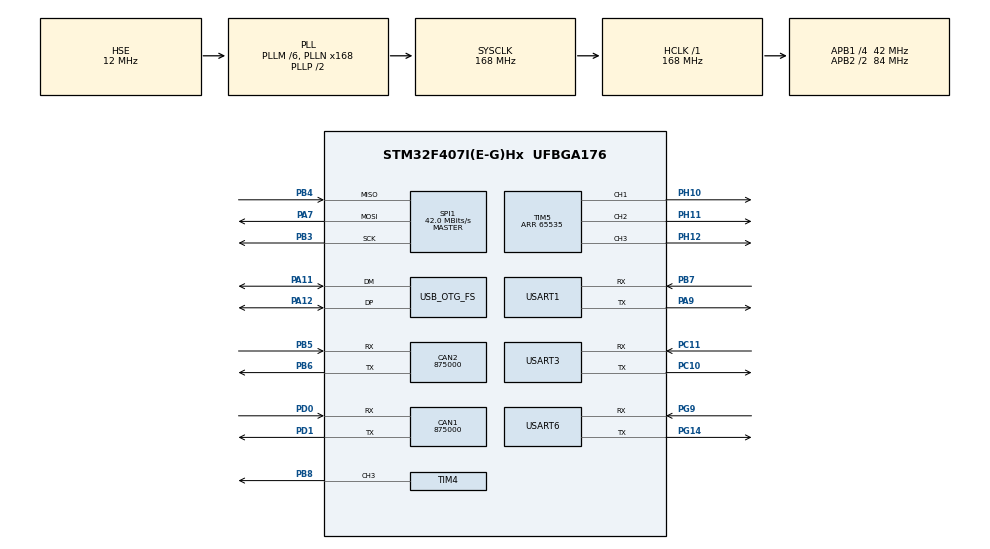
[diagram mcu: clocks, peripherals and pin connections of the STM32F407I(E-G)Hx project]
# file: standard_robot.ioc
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CAN1.CalculateBaudRate=875000
CAN1.CalculateTimeBit=1142
CAN1.CalculateTimeQuantum=380.95238095238096
CAN2.CalculateBaudRate=875000
CAN2.CalculateTimeBit=1142
CAN2.CalculateTimeQuantum=380.95238095238096
Dma.Request0=USART1_TX
Dma.Request1=USART1_RX
Dma.Request2=USART3_RX
Dma.Request3=USART6_RX
Dma.Request4=USART6_TX
Dma.Request5=SPI1_RX
Dma.Request6=SPI1_TX
Dma.SPI1_RX.5.Direction=DMA_PERIPH_TO_MEMORY
Dma.SPI1_RX.5.FIFOMode=DMA_FIFOMODE_DISABLE
Dma.SPI1_RX.5.Instance=DMA2_Stream2
Dma.SPI1_RX.5.MemDataAlignment=DMA_MDATAALIGN_BYTE
Dma.SPI1_RX.5.MemInc=DMA_MINC_ENABLE
Dma.SPI1_RX.5.Mode=DMA_NORMAL
Dma.SPI1_RX.5.PeriphDataAlignment=DMA_PDATAALIGN_BYTE
Dma.SPI1_RX.5.PeriphInc=DMA_PINC_DISABLE
Dma.SPI1_RX.5.Priority=DMA_PRIORITY_VERY_HIGH
Dma.SPI1_TX.6.Direction=DMA_MEMORY_TO_PERIPH
Dma.SPI1_TX.6.FIFOMode=DMA_FIFOMODE_DISABLE
Dma.SPI1_TX.6.Instance=DMA2_Stream3
Dma.SPI1_TX.6.MemDataAlignment=DMA_MDATAALIGN_BYTE
Dma.SPI1_TX.6.MemInc=DMA_MINC_ENABLE
Dma.SPI1_TX.6.Mode=DMA_NORMAL
Dma.SPI1_TX.6.PeriphDataAlignment=DMA_PDATAALIGN_BYTE
Dma.SPI1_TX.6.PeriphInc=DMA_PINC_DISABLE
Dma.SPI1_TX.6.Priority=DMA_PRIORITY_HIGH
Dma.USART1_RX.1.Direction=DMA_PERIPH_TO_MEMORY
Dma.USART1_RX.1.FIFOMode=DMA_FIFOMODE_DISABLE
Dma.USART1_RX.1.Instance=DMA2_Stream5
Dma.USART1_RX.1.MemDataAlignment=DMA_MDATAALIGN_BYTE
Dma.USART1_RX.1.MemInc=DMA_MINC_ENABLE
Dma.USART1_RX.1.Mode=DMA_CIRCULAR
Dma.USART1_RX.1.PeriphDataAlignment=DMA_PDATAALIGN_BYTE
Dma.USART1_RX.1.PeriphInc=DMA_PINC_DISABLE
Dma.USART1_RX.1.Priority=DMA_PRIORITY_MEDIUM
Dma.USART1_TX.0.Direction=DMA_MEMORY_TO_PERIPH
Dma.USART1_TX.0.FIFOMode=DMA_FIFOMODE_DISABLE
Dma.USART1_TX.0.Instance=DMA2_Stream7
Dma.USART1_TX.0.MemDataAlignment=DMA_MDATAALIGN_BYTE
Dma.USART1_TX.0.MemInc=DMA_MINC_ENABLE
Dma.USART1_TX.0.Mode=DMA_NORMAL
Dma.USART1_TX.0.PeriphDataAlignment=DMA_PDATAALIGN_BYTE
Dma.USART1_TX.0.PeriphInc=DMA_PINC_DISABLE
Dma.USART1_TX.0.Priority=DMA_PRIORITY_MEDIUM
Dma.USART3_RX.2.Direction=DMA_PERIPH_TO_MEMORY
Dma.USART3_RX.2.FIFOMode=DMA_FIFOMODE_DISABLE
Dma.USART3_RX.2.Instance=DMA1_Stream1
Dma.USART3_RX.2.MemDataAlignment=DMA_MDATAALIGN_BYTE
Dma.USART3_RX.2.MemInc=DMA_MINC_ENABLE
Dma.USART3_RX.2.Mode=DMA_CIRCULAR
Dma.USART3_RX.2.PeriphDataAlignment=DMA_PDATAALIGN_BYTE
Dma.USART3_RX.2.PeriphInc=DMA_PINC_DISABLE
Dma.USART3_RX.2.Priority=DMA_PRIORITY_MEDIUM
Dma.USART6_RX.3.Direction=DMA_PERIPH_TO_MEMORY
Dma.USART6_RX.3.FIFOMode=DMA_FIFOMODE_DISABLE
Dma.USART6_RX.3.Instance=DMA2_Stream1
Dma.USART6_RX.3.MemDataAlignment=DMA_MDATAALIGN_BYTE
Dma.USART6_RX.3.MemInc=DMA_MINC_ENABLE
Dma.USART6_RX.3.Mode=DMA_NORMAL
Dma.USART6_RX.3.PeriphDataAlignment=DMA_PDATAALIGN_BYTE
Dma.USART6_RX.3.PeriphInc=DMA_PINC_DISABLE
Dma.USART6_RX.3.Priority=DMA_PRIORITY_MEDIUM
Dma.USART6_TX.4.Direction=DMA_MEMORY_TO_PERIPH
Dma.USART6_TX.4.FIFOMode=DMA_FIFOMODE_DISABLE
Dma.USART6_TX.4.Instance=DMA2_Stream6
Dma.USART6_TX.4.MemDataAlignment=DMA_MDATAALIGN_BYTE
Dma.USART6_TX.4.MemInc=DMA_MINC_ENABLE
Dma.USART6_TX.4.Mode=DMA_NORMAL
Dma.USART6_TX.4.PeriphDataAlignment=DMA_PDATAALIGN_BYTE
Dma.USART6_TX.4.PeriphInc=DMA_PINC_DISABLE
Dma.USART6_TX.4.Priority=DMA_PRIORITY_MEDIUM
FREERTOS.Tasks01=defaultTask,0,128,StartDefaultTask,Default,NULL,Dynamic,NULL,NULL
Mcu.Family=STM32F4
Mcu.Name=STM32F407I(E-G)Hx
Mcu.Package=UFBGA176
NVIC.DMA1_Stream1_IRQn=true\:5\:0\:false\:false\:true\:true\:false\:true\:true
NVIC.DMA2_Stream1_IRQn=true\:5\:0\:false\:false\:true\:true\:false\:true\:true
NVIC.DMA2_Stream2_IRQn=true\:5\:0\:false\:false\:true\:true\:false\:true\:true
NVIC.DMA2_Stream3_IRQn=true\:5\:0\:false\:false\:true\:true\:false\:true\:true
NVIC.DMA2_Stream5_IRQn=true\:5\:0\:false\:false\:true\:true\:false\:true\:true
NVIC.DMA2_Stream6_IRQn=true\:5\:0\:false\:false\:true\:true\:false\:true\:true
NVIC.DMA2_Stream7_IRQn=true\:5\:0\:false\:false\:true\:true\:false\:true\:true
NVIC.OTG_FS_IRQn=true\:5\:0\:false\:false\:true\:true\:false\:true\:true
NVIC.PriorityGroup=NVIC_PRIORITYGROUP_4
NVIC.TIM8_TRG_COM_TIM14_IRQn=true\:15\:0\:false\:false\:true\:false\:false\:true\:true
NVIC.TimeBase=TIM8_TRG_COM_TIM14_IRQn
NVIC.TimeBaseIP=TIM14
NVIC.USART1_IRQn=true\:5\:0\:false\:false\:true\:true\:true\:true\:true
NVIC.USART3_IRQn=true\:5\:0\:false\:false\:true\:true\:true\:true\:true
NVIC.USART6_IRQn=true\:5\:0\:false\:false\:true\:true\:false\:true\:true
PA11.Mode=Device_Only
PA11.Signal=USB_OTG_FS_DM
PA12.Mode=Device_Only
PA12.Signal=USB_OTG_FS_DP
PA13.Mode=Serial_Wire
PA13.Signal=SYS_JTMS-SWDIO
PA14.Mode=Serial_Wire
PA14.Signal=SYS_JTCK-SWCLK
PA7.Mode=Full_Duplex_Master
PA7.Signal=SPI1_MOSI
PA9.Mode=Asynchronous
PA9.Signal=USART1_TX
PB3.Mode=Full_Duplex_Master
PB3.Signal=SPI1_SCK
PB4.Mode=Full_Duplex_Master
PB4.Signal=SPI1_MISO
PB5.Mode=CAN_Activate
PB5.Signal=CAN2_RX
PB6.Mode=CAN_Activate
PB6.Signal=CAN2_TX
PB7.Mode=Asynchronous
PB7.Signal=USART1_RX
PB8.Signal=S_TIM4_CH3
PC10.Mode=Asynchronous
PC10.Signal=USART3_TX
PC11.Mode=Asynchronous
PC11.Signal=USART3_RX
PD0.Mode=CAN_Activate
PD0.Signal=CAN1_RX
PD1.Mode=CAN_Activate
PD1.Signal=CAN1_TX
PG14.Mode=Asynchronous
PG14.Signal=USART6_TX
PG9.Mode=Asynchronous
PG9.Signal=USART6_RX
PH0-OSC_IN.Mode=HSE-External-Oscillator
PH0-OSC_IN.Signal=RCC_OSC_IN
PH1-OSC_OUT.Mode=HSE-External-Oscillator
PH1-OSC_OUT.Signal=RCC_OSC_OUT
PH10.Signal=S_TIM5_CH1
PH11.Signal=S_TIM5_CH2
PH12.Signal=S_TIM5_CH3
ProjectManager.HeapSize=0x2000
ProjectManager.StackSize=0x2000
ProjectManager.TargetToolchain=CMake
RCC.48MHZClocksFreq_Value=48000000
RCC.AHBFreq_Value=168000000
RCC.APB1CLKDivider=RCC_HCLK_DIV4
RCC.APB1Freq_Value=42000000
RCC.APB1TimFreq_Value=84000000
RCC.APB2CLKDivider=RCC_HCLK_DIV2
RCC.APB2Freq_Value=84000000
RCC.APB2TimFreq_Value=168000000
RCC.CortexFreq_Value=168000000
RCC.HCLKFreq_Value=168000000
RCC.HSE_VALUE=12000000
RCC.HSI_VALUE=16000000
RCC.LSE_VALUE=32768
RCC.PLLM=6
RCC.PLLN=168
RCC.PLLQ=7
RCC.SYSCLKFreq_VALUE=168000000
RCC.SYSCLKSource=RCC_SYSCLKSOURCE_PLLCLK
RCC.VCOOutputFreq_Value=336000000
SH.S_TIM4_CH3.0=TIM4_CH3,PWM Generation3 CH3
SH.S_TIM5_CH1.0=TIM5_CH1,PWM Generation1 CH1
SH.S_TIM5_CH2.0=TIM5_CH2,PWM Generation2 CH2
SH.S_TIM5_CH3.0=TIM5_CH3,PWM Generation3 CH3
SPI1.CalculateBaudRate=42.0 MBits/s
SPI1.Direction=SPI_DIRECTION_2LINES
SPI1.Mode=SPI_MODE_MASTER
SPI1.VirtualType=VM_MASTER
TIM4.Channel-PWM\ Generation3\ CH3=TIM_CHANNEL_3
TIM4.Prescaler=167
TIM5.Channel-PWM\ Generation1\ CH1=TIM_CHANNEL_1
TIM5.Channel-PWM\ Generation2\ CH2=TIM_CHANNEL_2
TIM5.Channel-PWM\ Generation3\ CH3=TIM_CHANNEL_3
TIM5.Period=65535
USART1.VirtualMode=VM_ASYNC
USART3.VirtualMode=VM_ASYNC
USART6.VirtualMode=VM_ASYNC
USB_DEVICE.CLASS_NAME_FS=CDC
USB_DEVICE.VirtualMode-CDC_FS=Cdc
USB_DEVICE.VirtualModeFS=Cdc_FS
USB_OTG_FS.VirtualMode=Device_Only
VP_FREERTOS_VS_CMSIS_V1.Mode=CMSIS_V1
VP_SYS_VS_tim14.Mode=TIM14
VP_TIM4_VS_ClockSourceINT.Mode=Internal
VP_TIM5_VS_ClockSourceINT.Mode=Internal
VP_USB_DEVICE_VS_USB_DEVICE_CDC_FS.Mode=CDC_FS
board=custom

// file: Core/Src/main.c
/* USER CODE BEGIN Header */
/**
  ******************************************************************************
  * @file           : main.c
  * @brief          : Main program body
  ******************************************************************************
  * @attention
  *
  * Copyright (c) 2026 STMicroelectronics.
  * All rights reserved.
  *
  * This software is licensed under terms that can be found in the LICENSE file
  * in the root directory of this software component.
  * If no LICENSE file comes with this software, it is provided AS-IS.
  *
  ******************************************************************************
  */
/* USER CODE END Header */
#include "main.h"
#include "cmsis_os.h"
#include "can.h"
#include "dma.h"
#include "spi.h"
#include "tim.h"
#include "usart.h"
#include "usb_device.h"
#include "gpio.h"

/* USER CODE BEGIN Includes */
#include "bsp_init.h"
/* USER CODE END Includes */

void SystemClock_Config(void);
void MX_FREERTOS_Init(void);

int main(void)
{

  /* MCU Configuration--------------------------------------------------------*/

  /* Reset of all peripherals, Initializes the Flash interface and the Systick. */
  HAL_Init();

  /* Configure the system clock */
  SystemClock_Config();

  /* Initialize all configured peripherals */
  MX_GPIO_Init();
  MX_DMA_Init();
  MX_CAN1_Init();
  MX_CAN2_Init();
  MX_USART1_UART_Init();
  MX_USART3_UART_Init();
  MX_USART6_UART_Init();
  MX_SPI1_Init();
  MX_TIM4_Init();
  MX_TIM5_Init();
  /* USER CODE BEGIN 2 */
  bsp_init();
  /* USER CODE END 2 */

  /* Call init function for freertos objects (in cmsis_os2.c) */
  MX_FREERTOS_Init();

  /* Start scheduler */
  osKernelStart();

  /* We should never get here as control is now taken by the scheduler */

  /* Infinite loop */
  while (1)
  {

  }
}

void SystemClock_Config(void)
{
  RCC_OscInitTypeDef RCC_OscInitStruct = {0};
  RCC_ClkInitTypeDef RCC_ClkInitStruct = {0};

  /** Configure the main internal regulator output voltage
  */
  __HAL_RCC_PWR_CLK_ENABLE();
  __HAL_PWR_VOLTAGESCALING_CONFIG(PWR_REGULATOR_VOLTAGE_SCALE1);

  /** Initializes the RCC Oscillators according to the specified parameters
  * in the RCC_OscInitTypeDef structure.
  */
  RCC_OscInitStruct.OscillatorType = RCC_OSCILLATORTYPE_HSE;
  RCC_OscInitStruct.HSEState = RCC_HSE_ON;
  RCC_OscInitStruct.PLL.PLLState = RCC_PLL_ON;
  RCC_OscInitStruct.PLL.PLLSource = RCC_PLLSOURCE_HSE;
  RCC_OscInitStruct.PLL.PLLM = 6;
  RCC_OscInitStruct.PLL.PLLN = 168;
  RCC_OscInitStruct.PLL.PLLP = RCC_PLLP_DIV2;
  RCC_OscInitStruct.PLL.PLLQ = 7;
  if (HAL_RCC_OscConfig(&RCC_OscInitStruct) != HAL_OK)
  {
    Error_Handler();
  }

  /** Initializes the CPU, AHB and APB buses clocks
  */
  RCC_ClkInitStruct.ClockType = RCC_CLOCKTYPE_HCLK|RCC_CLOCKTYPE_SYSCLK
                              |RCC_CLOCKTYPE_PCLK1|RCC_CLOCKTYPE_PCLK2;
  RCC_ClkInitStruct.SYSCLKSource = RCC_SYSCLKSOURCE_PLLCLK;
  RCC_ClkInitStruct.AHBCLKDivider = RCC_SYSCLK_DIV1;
  RCC_ClkInitStruct.APB1CLKDivider = RCC_HCLK_DIV4;
  RCC_ClkInitStruct.APB2CLKDivider = RCC_HCLK_DIV2;

  if (HAL_RCC_ClockConfig(&RCC_ClkInitStruct, FLASH_LATENCY_5) != HAL_OK)
  {
    Error_Handler();
  }
}

void HAL_TIM_PeriodElapsedCallback(TIM_HandleTypeDef *htim)
{
  if (htim->Instance == TIM14)
  {
    HAL_IncTick();
  }
}

void Error_Handler(void)
{
  __disable_irq();
  while (1)
  {
  }
}

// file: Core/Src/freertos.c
/* USER CODE BEGIN Header */
/**
  ******************************************************************************
  * File Name          : freertos.c
  * Description        : Code for freertos applications
  ******************************************************************************
  * @attention
  *
  * Copyright (c) 2026 STMicroelectronics.
  * All rights reserved.
  *
  * This software is licensed under terms that can be found in the LICENSE file
  * in the root directory of this software component.
  * If no LICENSE file comes with this software, it is provided AS-IS.
  *
  ******************************************************************************
  */
/* USER CODE END Header */

#include "FreeRTOS.h"
#include "task.h"
#include "main.h"
#include "cmsis_os.h"

/* USER CODE BEGIN Includes */
#include "task_init.h"
/* USER CODE END Includes */

osThreadId defaultTaskHandle;
/* USER CODE BEGIN FunctionPrototypes */
extern void test_task(void const* argument);
/* USER CODE END FunctionPrototypes */

void StartDefaultTask(void const * argument);

extern void MX_USB_DEVICE_Init(void);
void MX_FREERTOS_Init(void); /* (MISRA C 2004 rule 8.1) */

/* GetIdleTaskMemory prototype (linked to static allocation support) */
void vApplicationGetIdleTaskMemory( StaticTask_t **ppxIdleTaskTCBBuffer, StackType_t **ppxIdleTaskStackBuffer, uint32_t *pulIdleTaskStackSize );

/* USER CODE BEGIN GET_IDLE_TASK_MEMORY */
static StaticTask_t xIdleTaskTCBBuffer;
static StackType_t xIdleStack[configMINIMAL_STACK_SIZE];

void vApplicationGetIdleTaskMemory( StaticTask_t **ppxIdleTaskTCBBuffer, StackType_t **ppxIdleTaskStackBuffer, uint32_t *pulIdleTaskStackSize )
{
  *ppxIdleTaskTCBBuffer = &xIdleTaskTCBBuffer;
  *ppxIdleTaskStackBuffer = &xIdleStack[0];
  *pulIdleTaskStackSize = configMINIMAL_STACK_SIZE;
  /* place for user code */
}
/* USER CODE END GET_IDLE_TASK_MEMORY */

void MX_FREERTOS_Init(void) {

  /* Create the thread(s) */
  /* definition and creation of defaultTask */
  osThreadDef(defaultTask, StartDefaultTask, osPriorityNormal, 0, 128);
  defaultTaskHandle = osThreadCreate(osThread(defaultTask), NULL);
  /* USER CODE BEGIN RTOS_THREADS */
  /* add threads, ... */
  task_init();
  /* USER CODE END RTOS_THREADS */

}

void StartDefaultTask(void const * argument)
{
  /* init code for USB_DEVICE */
  MX_USB_DEVICE_Init();
  for(;;)
  {
    osDelay(1);
  }
}
